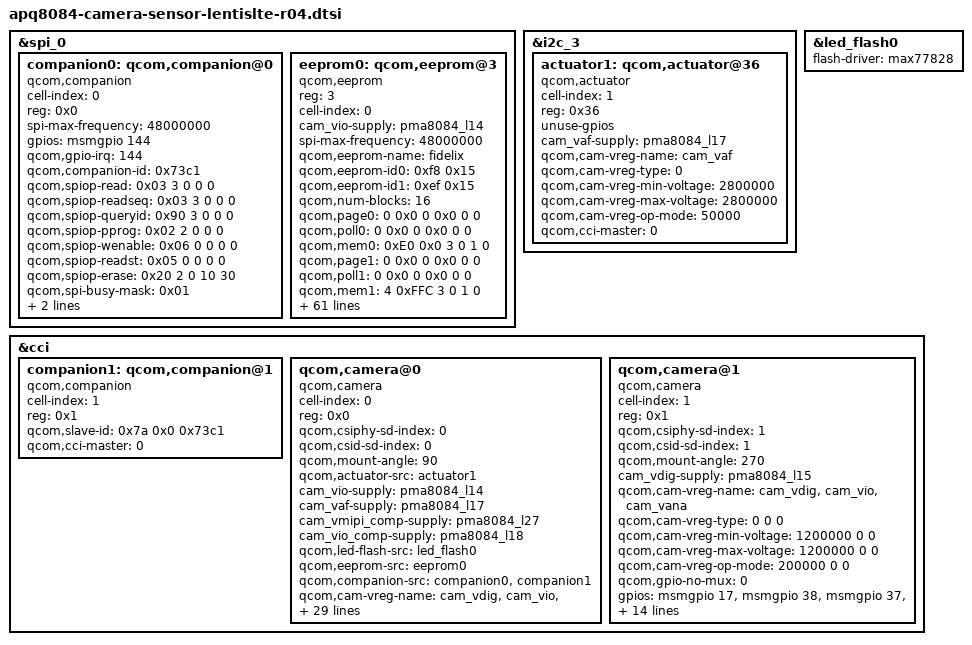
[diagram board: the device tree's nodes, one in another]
/*
 * Copyright (c) 2014, The Linux Foundation. All rights reserved.
 *
 * This program is free software; you can redistribute it and/or modify
 * it under the terms of the GNU General Public License version 2 and
 * only version 2 as published by the Free Software Foundation.
 *
 * This program is distributed in the hope that it will be useful,
 * but WITHOUT ANY WARRANTY; without even the implied warranty of
 * MERCHANTABILITY or FITNESS FOR A PARTICULAR PURPOSE.  See the
 * GNU General Public License for more details.
 */

&spi_0 {
	companion0: qcom,companion@0 {
		compatible = "qcom,companion";
		cell-index = <0>;
		reg = <0x0>;
		spi-max-frequency = <48000000>;
		gpios = <&msmgpio 144 0>; /* COMP_SPI_INT */
		qcom,gpio-irq = <144>;
		qcom,companion-id = <0x73c1>;
		qcom,spiop-read = <0x03 3 0 0 0>;
		qcom,spiop-readseq = <0x03 3 0 0 0>;
		qcom,spiop-queryid = <0x90 3 0 0 0>;
		qcom,spiop-pprog = <0x02 2 0 0 0>;
		qcom,spiop-wenable = <0x06 0 0 0 0>;
		qcom,spiop-readst = <0x05 0 0 0 0>;
		qcom,spiop-erase = <0x20 2 0 10 30>;
		qcom,spi-busy-mask = <0x01>;
		qcom,spi-page-size = <0x256>;
		qcom,spi-erase-size = <0x4096>;
	};

	eeprom0: qcom,eeprom@3 {
		compatible = "qcom,eeprom";
		reg = <3>;
		cell-index = <0>;
		cam_vio-supply = <&pma8084_l14>;
		spi-max-frequency = <48000000>;
		qcom,eeprom-name = "fidelix";
		qcom,eeprom-id0 = <0xf8 0x15>;
		qcom,eeprom-id1 = <0xef 0x15>;

		qcom,num-blocks = <16>;
		qcom,page0 = <0 0x0 0 0x0 0 0>;
		qcom,poll0 = <0 0x0 0 0x0 0 0>;
		qcom,mem0 = <0xE0 0x0 3 0 1 0>;
		qcom,page1 = <0 0x0 0 0x0 0 0>;
		qcom,poll1 = <0 0x0 0 0x0 0 0>;
		qcom,mem1 = <4 0xFFC 3 0 1 0>;
		qcom,page2 = <0 0x0 0 0x0 0 0>;
		qcom,poll2 = <0 0x0 0 0x0 0 0>;
		qcom,mem2 = <0x140 0x1000 3 0 1 0>;
		qcom,page3 = <0 0x0 0 0x0 0 0>;
		qcom,poll3 = <0 0x0 0 0x0 0 0>;
		qcom,mem3 = <4 0x1FFC 3 0 1 0>;
		qcom,page4 = <0 0x0 0 0x0 0 0>;
		qcom,poll4 = <0 0x0 0 0x0 0 0>;
		qcom,mem4 = <0x20 0x2000 3 0 1 0>;
		qcom,page5 = <0 0x0 0 0x0 0 0>;
		qcom,poll5 = <0 0x0 0 0x0 0 0>;
		qcom,mem5 = <4 0x2FFC 3 0 1 0>;
		qcom,page6 = <0 0x0 0 0x0 0 0>;
		qcom,poll6 = <0 0x0 0 0x0 0 0>;
		qcom,mem6 = <0x19F0 0x3000 3 0 1 0>;
		qcom,page7 = <0 0x0 0 0x0 0 0>;
		qcom,poll7 = <0 0x0 0 0x0 0 0>;
		qcom,mem7 = <4 0x4FFC 3 0 1 0>;
		qcom,page8 = <0 0x0 0 0x0 0 0>;
		qcom,poll8 = <0 0x0 0 0x0 0 0>;
		qcom,mem8 = <0x410 0x5000 3 0 1 0>;
		qcom,page9 = <0 0x0 0 0x0 0 0>;
		qcom,poll9 = <0 0x0 0 0x0 0 0>;
		qcom,mem9 = <4 0x8FFC 3 0 1 0>;
		qcom,page10 = <0 0x0 0 0x0 0 0>;
		qcom,poll10 = <0 0x0 0 0x0 0 0>;
		qcom,mem10 = <0x6240 0x9000 3 0 1 0>;
		qcom,page11 = <0 0x0 0 0x0 0 0>;
		qcom,poll11 = <0 0x0 0 0x0 0 0>;
		qcom,mem11 = <4 0xFFFC 3 0 1 0>;
		qcom,page12 = <0 0x0 0 0x0 0 0>;
		qcom,poll12 = <0 0x0 0 0x0 0 0>;
		qcom,mem12 = <0x19F0 0x15000 3 0 1 0>;
		qcom,page13 = <0 0x0 0 0x0 0 0>;
		qcom,poll13 = <0 0x0 0 0x0 0 0>;
		qcom,mem13 = <4 0x16FFC 3 0 1 0>;
		qcom,page14 = <0 0x0 0 0x0 0 0>;
		qcom,poll14 = <0 0x0 0 0x0 0 0>;
		qcom,mem14 = <0x13FFC 0x17000 3 0 1 0>;
		qcom,page15 = <0 0x0 0 0x0 0 0>;
		qcom,poll15 = <0 0x0 0 0x0 0 0>;
		qcom,mem15 = <4 0x2AFFC 3 0 1 0>;

		qcom,cam-vreg-name = "cam_vio";
		qcom,cam-vreg-type = <0>;
		qcom,cam-vreg-min-voltage = <1800000>;
		qcom,cam-vreg-max-voltage = <1800000>;
		qcom,cam-vreg-op-mode = <5000>;
		qcom,cam-power-seq-type = "sensor_vreg";
		qcom,cam-power-seq-val = "cam_vio";
		qcom,cam-power-seq-cfg-val = <1>;
		qcom,cam-power-seq-delay = <1>;

		qcom,spiop-read = <0x03 3 0 0 0>;
		qcom,spiop-readseq = <0x03 3 0 0 0>;
		qcom,spiop-queryid = <0x90 3 0 0 0>;
		qcom,spiop-pprog = <0x02 3 0 3 3>;
		qcom,spiop-wenable = <0x06 0 0 0 0>;
		qcom,spiop-readst = <0x05 0 0 0 0>;
		qcom,spiop-erase = <0x20 3 0 10 30>;
		qcom,spi-busy-mask = <0x01>;
		qcom,spi-page-size = <256>;
		qcom,spi-erase-size = <4096>;
	};
};

&i2c_3  { /* BLSP2 QUP6 */
	actuator1: qcom,actuator@36 {
		compatible = "qcom,actuator";
		cell-index = <1>;
		reg = <0x36>;
		unuse-gpios;
		cam_vaf-supply = <&pma8084_l17>;
		qcom,cam-vreg-name = "cam_vaf";
		qcom,cam-vreg-type = <0>;
		qcom,cam-vreg-min-voltage = <2800000>;
		qcom,cam-vreg-max-voltage = <2800000>;
		qcom,cam-vreg-op-mode = <50000>;
		qcom,cci-master = <0>;
	};
};

&led_flash0 {
	flash-driver = "max77828";
};

&cci {
    companion1: qcom,companion@1  {
		cell-index = <1>;
		compatible = "qcom,companion";
		reg = <0x1>;
		qcom,slave-id = <0x7a 0x0 0x73c1>;
		qcom,cci-master = <0>;
		status = "ok";
	};

	qcom,camera@0 {
		cell-index = <0>;
		compatible = "qcom,camera";
		reg = <0x0>;
		qcom,csiphy-sd-index = <0>;
		qcom,csid-sd-index = <0>;
		qcom,mount-angle = <90>;
		qcom,actuator-src = <&actuator1>;
		/*cam_vdig-supply = <&pma8084_l4>;*/
		cam_vio-supply = <&pma8084_l14>;
		cam_vaf-supply = <&pma8084_l17>;
		/*cam_vana-supply = <&pma8084_l17>;*/
		cam_vmipi_comp-supply = <&pma8084_l27>;
		cam_vio_comp-supply = <&pma8084_l18>;
		qcom,led-flash-src = <&led_flash0>;
		qcom,eeprom-src = <&eeprom0>;
		qcom,companion-src = <&companion0 &companion1>;
		qcom,cam-vreg-name = "cam_vdig", "cam_vio", "cam_vaf", "cam_vana", "cam_vmipi_comp", "cam_vio_comp", "cam_vdd_ois", "cam_vm_ois";
		qcom,cam-vreg-type = <0 0 0 0 0 0 0 0>;
		/* If min & max voltage is 0, it means that regulator is disabled */
		qcom,cam-vreg-min-voltage = <0 1800000 2800000 0 1000000 1800000 0 0>;
		qcom,cam-vreg-max-voltage = <0 1800000 2800000 0 1000000 1800000 0 0>;
		qcom,cam-vreg-op-mode = <0 5000 50000 0 50000 50000 0 0>;
		qcom,gpio-no-mux = <0>;
		gpios = <&msmgpio 15 0>, /* MCLK */
			<&msmgpio 36 0>, /* RESET */
			<&msmgpio 35 0>, /* A 2.8V */
			<&pma8084_gpios 17 0>, /* COMP_EN */
			<&msmgpio 25 0>, /* COMPANION_RSTN */
			<&pma8084_gpios 7 0>, /* TORCH_EN */
			<&pma8084_gpios 12 0>;          /* FLASH_EN */
		qcom,gpio-reset = <1>;
		qcom,gpio-vana = <2>;
		qcom,gpio-comp = <3>;
		qcom,gpio-comprstn = <4>;
		qcom,gpio-torch-en = <5>;
		qcom,gpio-flash-en = <6>;
		/* Special case : E */
		/* Camera driver doesn't have to request gpio about torch pin and flash pin */
		qcom,gpio-req-tbl-num = <0 1 2 3 4>;
		qcom,gpio-req-tbl-flags = <1 0 0 0 0>;
		qcom,gpio-req-tbl-label = "CAMIF_MCLK", "CAM_RESET1", "CAM_VANA",
                                           "CAM_COMP_GPIO", "CAM_COMPRSTN_GPIO";
		/* Special case : X */
		qcom,gpio-set-tbl-delay = <1000 30000>;
		qcom,gpio-comp-spi-irq = <144>;/* COMP_SPI_INT */
		qcom,sensor-position = <0>;
		qcom,sensor-mode = <1>;
		qcom,cci-master = <0>;
		status = "ok";
	};

	qcom,camera@1 {
		cell-index = <1>;
		compatible = "qcom,camera";
		reg = <0x1>;
		qcom,csiphy-sd-index = <1>;
		qcom,csid-sd-index = <1>;
		qcom,mount-angle = <270>;
		cam_vdig-supply = <&pma8084_l15>;
		qcom,cam-vreg-name ="cam_vdig", "cam_vio", "cam_vana";
		qcom,cam-vreg-type = <0 0 0>;
		qcom,cam-vreg-min-voltage = <1200000 0 0>;
		qcom,cam-vreg-max-voltage = <1200000 0 0>;
		qcom,cam-vreg-op-mode = <200000 0 0>;
		qcom,gpio-no-mux = <0>;
		gpios = <&msmgpio 17 0>, /* MCLK */
			<&msmgpio 38 0>, /* RESET */
			<&msmgpio 37 0>, /* STNBY  */
			<&msmgpio 13 0>, /* IO 1.8V */
			<&msmgpio 14 0>; /* A 2.8V */
		qcom,gpio-vt-reset = <1>;
		qcom,gpio-vt-standby = <2>;
		qcom,gpio-vt-vio = <3>;
		qcom,gpio-vt-vana = <4>;
		qcom,gpio-req-tbl-num = <0 1 2 3 4>;
		qcom,gpio-req-tbl-flags = <1 0 0 0 0>;
		qcom,gpio-req-tbl-label = "CAM_VT_MCLK", "CAM_VT_RESET", "CAM_VT_STNBY",
                                          "CAM_VT_VIO", "CAM_VT_VANA";
		qcom,gpio-set-tbl-delay = <1000 1000 30000>;
		qcom,sensor-position = <1>;
		qcom,sensor-mode = <1>;
		qcom,cci-master = <1>;
		status = "ok";
	};
};
